# HDSC_HC32F4A0 register map
Vendor: HDSC; Series: ARMCM4; File version: 1.0
CPU: CM4 r0p1, little endian, MPU, FPU, 4 interrupt priority bits
Registers are 32-bit, read-write, reset 0x0 unless marked. A register's access mark holds for its fields unless they carry their own. Offsets are from the block's base; [hi:lo] are bit positions; {n}, {i} and the like mark numbered series.

## CRC
Base 0x40008C00
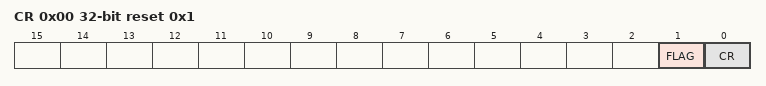
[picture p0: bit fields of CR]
0x00 CR reset 0x1
  [1] FLAG ro, [0] CR
0x04 RESLT
{0x80+4i} DAT{i} (i=0..31)

## CTC
Base 0x40049C00
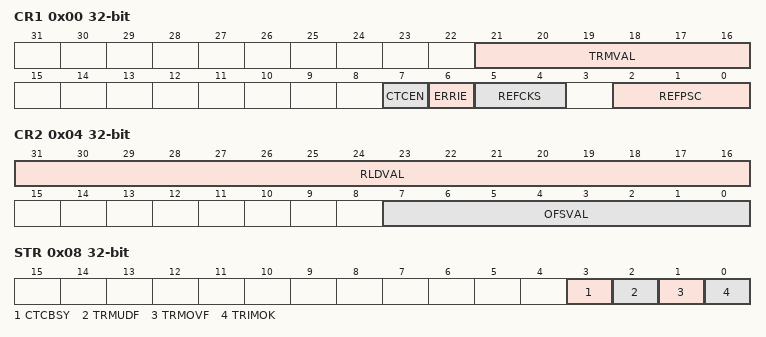
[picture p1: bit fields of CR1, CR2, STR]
0x00 CR1
  [21:16] TRMVAL, [7] CTCEN, [6] ERRIE, [5:4] REFCKS, [2:0] REFPSC
0x04 CR2
  [31:16] RLDVAL, [7:0] OFSVAL
0x08 STR ro
  [3] CTCBSY, [2] TRMUDF, [1] TRMOVF, [0] TRIMOK

## DAC1 — desc DAC
Base 0x40041000
Same registers: DAC2 0x40041400
0x00 DADR1 16-bit
0x02 DADR2 16-bit
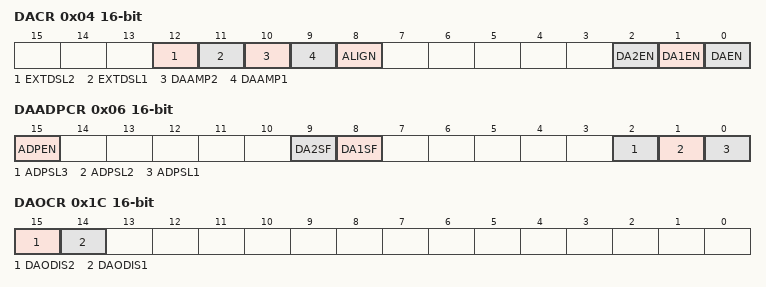
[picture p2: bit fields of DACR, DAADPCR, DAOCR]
0x04 DACR 16-bit
  [12] EXTDSL2, [11] EXTDSL1, [10] DAAMP2, [9] DAAMP1, [8] ALIGN, [2] DA2EN, [1] DA1EN, [0] DAEN
0x06 DAADPCR 16-bit
  [15] ADPEN, [9] DA2SF ro, [8] DA1SF ro, [2] ADPSL3, [1] ADPSL2, [0] ADPSL1
0x1C DAOCR 16-bit
  [15] DAODIS2, [14] DAODIS1

## DBGC
Base 0xE0042000
{0x0+4i} AUTHID{i} (i=0..2)
0x0C RESV0
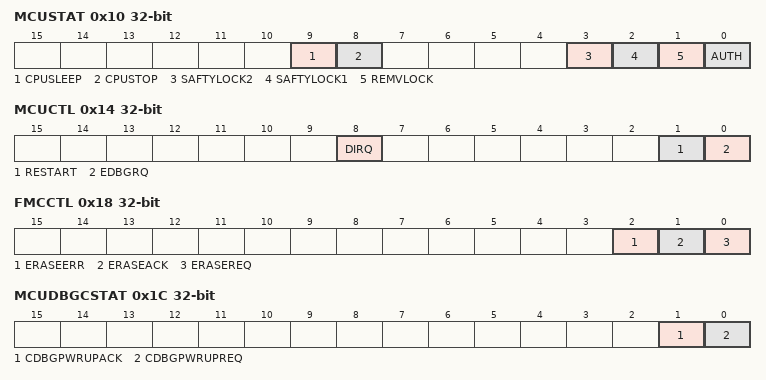
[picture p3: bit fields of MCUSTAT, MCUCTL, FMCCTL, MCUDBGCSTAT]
0x10 MCUSTAT
  [9] CPUSLEEP, [8] CPUSTOP, [3] SAFTYLOCK2, [2] SAFTYLOCK1, [1] REMVLOCK, [0] AUTH
0x14 MCUCTL
  [8] DIRQ, [1] RESTART, [0] EDBGRQ
0x18 FMCCTL
  [2] ERASEERR, [1] ERASEACK, [0] ERASEREQ
0x1C MCUDBGCSTAT
  [1] CDBGPWRUPACK, [0] CDBGPWRUPREQ
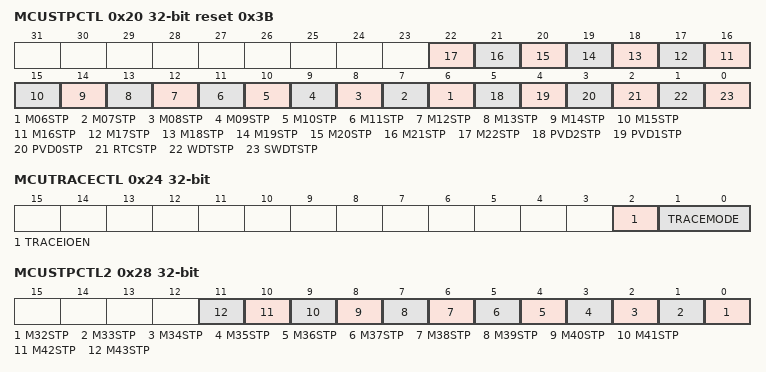
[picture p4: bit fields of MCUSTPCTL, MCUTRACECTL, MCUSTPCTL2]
0x20 MCUSTPCTL reset 0x3B
  [n] M{n:02}STP (n=6..22), [5] PVD2STP, [4] PVD1STP, [3] PVD0STP, [2] RTCSTP, [1] WDTSTP, [0] SWDTSTP
0x24 MCUTRACECTL
  [2] TRACEIOEN, [1:0] TRACEMODE
0x28 MCUSTPCTL2
  [n-32] M{n}STP (n=32..43)

## DCU1 — desc DCU
Base 0x40056000
Same registers: DCU2 0x40056400, DCU3 0x40056800, DCU4 0x40056C00
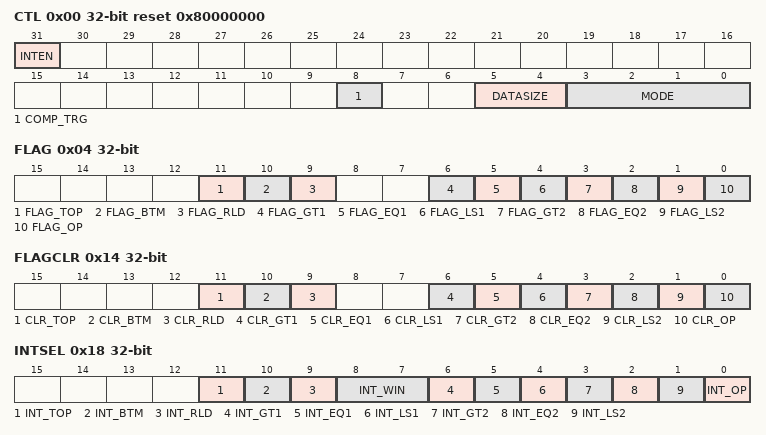
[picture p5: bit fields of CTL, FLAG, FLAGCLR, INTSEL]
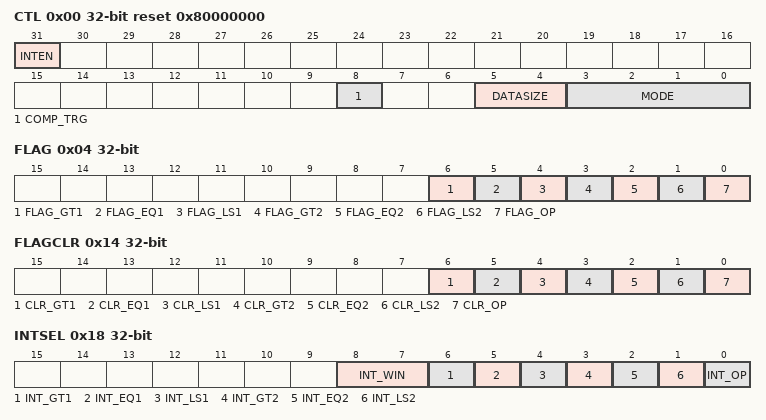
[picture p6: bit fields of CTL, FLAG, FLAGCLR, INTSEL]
0x00 CTL reset 0x80000000
  [31] INTEN, [8] COMP_TRG, [5:4] DATASIZE, [3:0] MODE
0x04 FLAG ro
  [11] FLAG_TOP, [10] FLAG_BTM, [9] FLAG_RLD, [6] FLAG_GT1, [5] FLAG_EQ1, [4] FLAG_LS1, [3] FLAG_GT2, [2] FLAG_EQ2, [1] FLAG_LS2, [0] FLAG_OP
{0x8+4i} DATA{i} (i=0..2)
0x14 FLAGCLR wo
  [11] CLR_TOP rw, [10] CLR_BTM rw, [9] CLR_RLD rw, [6] CLR_GT1, [5] CLR_EQ1, [4] CLR_LS1, [3] CLR_GT2, [2] CLR_EQ2, [1] CLR_LS2, [0] CLR_OP
0x18 INTSEL
  [11] INT_TOP, [10] INT_BTM, [9] INT_RLD, [8:7] INT_WIN, [6] INT_GT1, [5] INT_EQ1, [4] INT_LS1, [3] INT_GT2, [2] INT_EQ2, [1] INT_LS2, [0] INT_OP

## DCU5 — desc DCU
Base 0x40057000
Same registers: DCU6 0x40057400, DCU7 0x40057800, DCU8 0x40057C00
0x00 CTL reset 0x80000000
  [31] INTEN, [8] COMP_TRG, [5:4] DATASIZE, [3:0] MODE
0x04 FLAG ro
  [6] FLAG_GT1, [5] FLAG_EQ1, [4] FLAG_LS1, [3] FLAG_GT2, [2] FLAG_EQ2, [1] FLAG_LS2, [0] FLAG_OP
{0x8+4i} DATA{i} (i=0..2)
0x14 FLAGCLR wo
  [6] CLR_GT1, [5] CLR_EQ1, [4] CLR_LS1, [3] CLR_GT2, [2] CLR_EQ2, [1] CLR_LS2, [0] CLR_OP
0x18 INTSEL
  [8:7] INT_WIN, [6] INT_GT1, [5] INT_EQ1, [4] INT_LS1, [3] INT_GT2, [2] INT_EQ2, [1] INT_LS2, [0] INT_OP

## DMA1 — desc DMA
Base 0x40053000
Same registers: DMA2 0x40053400
0x00 EN
  [0] EN
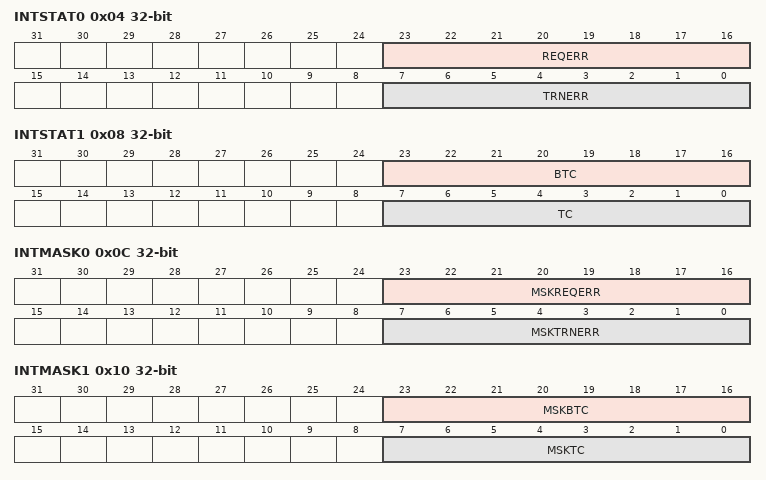
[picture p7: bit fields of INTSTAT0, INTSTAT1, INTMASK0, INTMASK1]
0x04 INTSTAT0 ro
  [23:16] REQERR, [7:0] TRNERR
0x08 INTSTAT1 ro
  [23:16] BTC, [7:0] TC
0x0C INTMASK0
  [23:16] MSKREQERR, [7:0] MSKTRNERR
0x10 INTMASK1
  [23:16] MSKBTC, [7:0] MSKTC
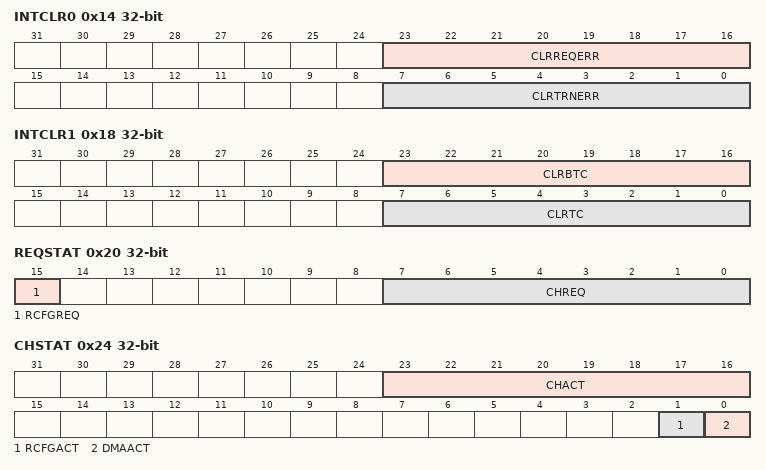
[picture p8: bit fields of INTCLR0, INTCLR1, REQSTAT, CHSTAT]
0x14 INTCLR0
  [23:16] CLRREQERR, [7:0] CLRTRNERR
0x18 INTCLR1
  [23:16] CLRBTC, [7:0] CLRTC
0x1C CHEN
  [7:0] CHEN
0x20 REQSTAT ro
  [15] RCFGREQ, [7:0] CHREQ
0x24 CHSTAT ro
  [23:16] CHACT, [1] RCFGACT, [0] DMAACT
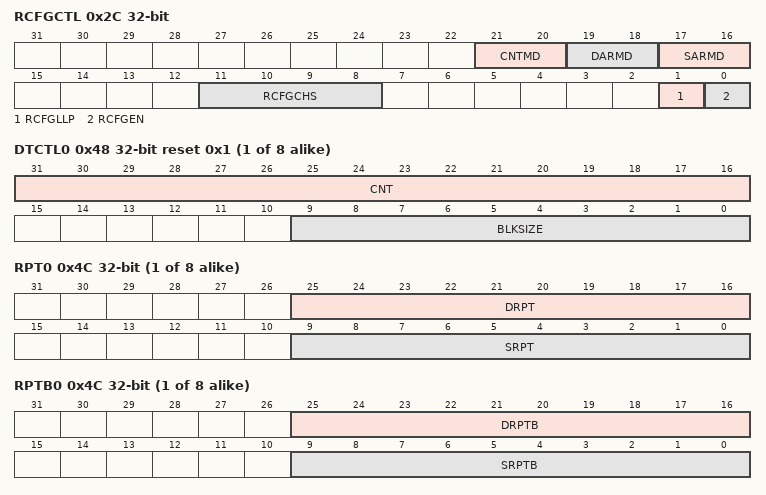
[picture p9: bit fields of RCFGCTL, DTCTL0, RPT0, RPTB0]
0x2C RCFGCTL
  [21:20] CNTMD, [19:18] DARMD, [17:16] SARMD, [11:8] RCFGCHS, [1] RCFGLLP, [0] RCFGEN
0x34 CHENCLR
  [7:0] CHENCLR
{0x40+0x40*i} SAR{i} (i=0..7)
{0x44+0x40*i} DAR{i} (i=0..7)
{0x48+0x40*i} DTCTL{i} reset 0x1 (i=0..7)
  [31:16] CNT, [9:0] BLKSIZE
{0x4C+0x40*i} RPT{i} (i=0..7)
  [25:16] DRPT, [9:0] SRPT
{0x4C+0x40*i} RPTB{i} (i=0..7)
  [25:16] DRPTB, [9:0] SRPTB
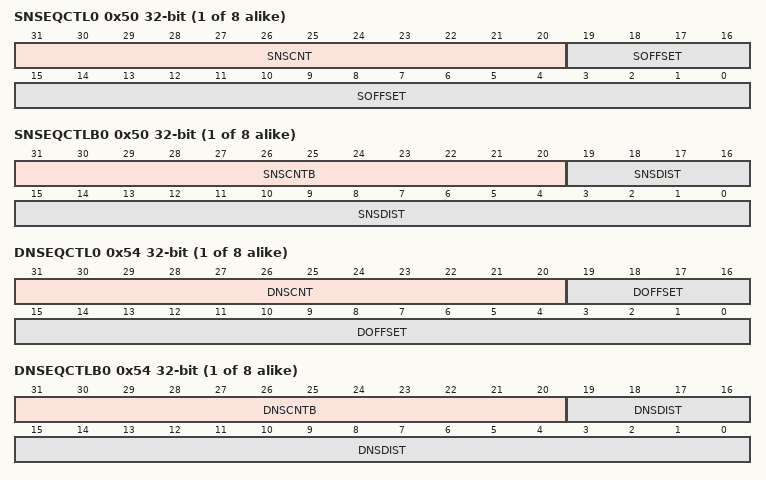
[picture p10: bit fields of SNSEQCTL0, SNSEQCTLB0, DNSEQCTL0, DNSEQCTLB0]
{0x50+0x40*i} SNSEQCTL{i} (i=0..7)
  [31:20] SNSCNT, [19:0] SOFFSET
{0x50+0x40*i} SNSEQCTLB{i} (i=0..7)
  [31:20] SNSCNTB, [19:0] SNSDIST
{0x54+0x40*i} DNSEQCTL{i} (i=0..7)
  [31:20] DNSCNT, [19:0] DOFFSET
{0x54+0x40*i} DNSEQCTLB{i} (i=0..7)
  [31:20] DNSCNTB, [19:0] DNSDIST
{0x58+0x40*i} LLP{i} (i=0..7)
  [31:2] LLP
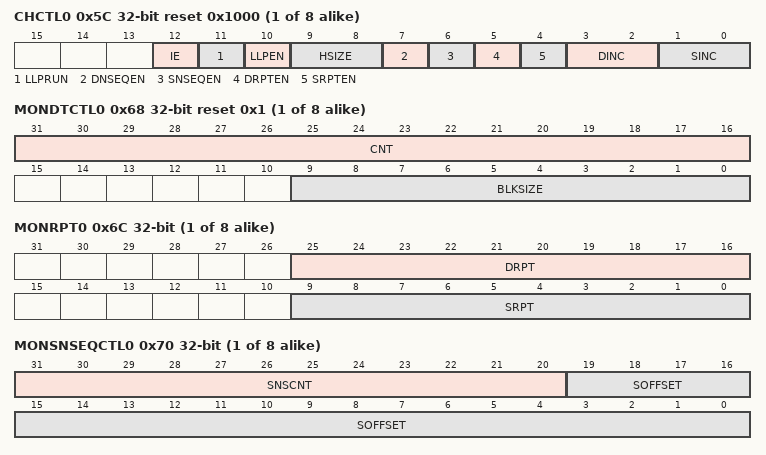
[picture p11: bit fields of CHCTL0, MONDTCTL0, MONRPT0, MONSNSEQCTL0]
{0x5C+0x40*i} CHCTL{i} reset 0x1000 (i=0..7)
  [12] IE, [11] LLPRUN, [10] LLPEN, [9:8] HSIZE, [7] DNSEQEN, [6] SNSEQEN, [5] DRPTEN, [4] SRPTEN, [3:2] DINC, [1:0] SINC
{0x60+0x40*i} MONSAR{i} ro (i=0..7)
{0x64+0x40*i} MONDAR{i} ro (i=0..7)
{0x68+0x40*i} MONDTCTL{i} ro reset 0x1 (i=0..7)
  [31:16] CNT, [9:0] BLKSIZE
{0x6C+0x40*i} MONRPT{i} ro (i=0..7)
  [25:16] DRPT, [9:0] SRPT
{0x70+0x40*i} MONSNSEQCTL{i} ro (i=0..7)
  [31:20] SNSCNT, [19:0] SOFFSET
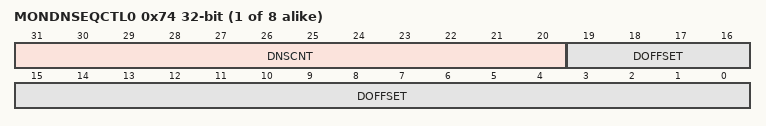
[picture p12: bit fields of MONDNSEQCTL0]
{0x74+0x40*i} MONDNSEQCTL{i} ro (i=0..7)
  [31:20] DNSCNT, [19:0] DOFFSET
